# ET6801 register map
Vendor: ETMCU Inc.; File version: v0.0.1
CPU: CM7 r2p1, little endian, MPU, FPU, I-cache, D-cache, ITCM, DTCM, 4 interrupt priority bits
Registers are 32-bit, read-write, reset 0x0 unless marked. A register's access mark holds for its fields unless they carry their own. Offsets are from the block's base; [hi:lo] are bit positions; {n}, {i} and the like mark numbered series.

## I2C0 — Provide an overview of the purpose and functionality of the peripheral: I2C
Base 0x40508000
Same registers: I2C1 0x40509000, I2C2 0x4050A000
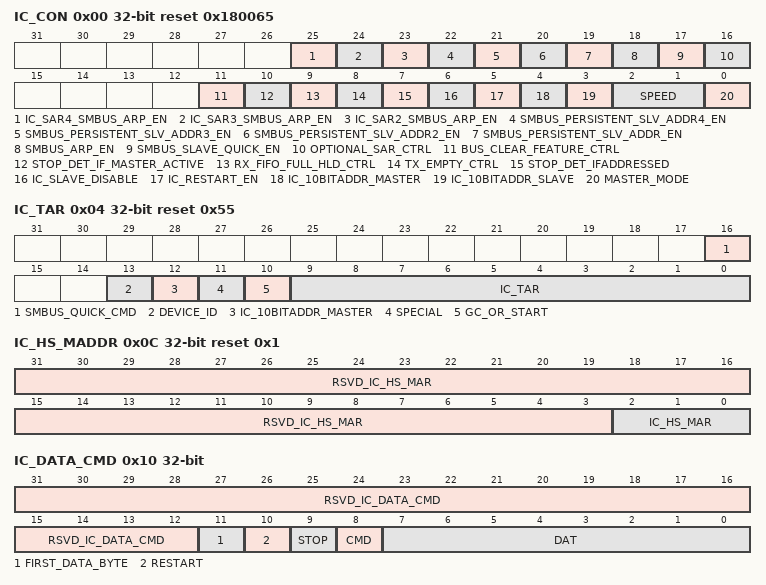
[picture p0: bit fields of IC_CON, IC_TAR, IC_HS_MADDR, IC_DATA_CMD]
0x00 IC_CON reset 0x180065 — I2C Control Register
  [25] IC_SAR4_SMBUS_ARP_EN — This bit controls whether DW_apb_i2c should enable Address Resolution Logic in SMBus Mode for IC_SAR4 Slave Address. The Slave mode will decode the Address Resolution Protocol commands and respond to it. The DW_apb_i2c slave also includes the generation/validity of PEC byte for Address Resolution Protocol commands. This bit is applicable only in Slave mode
  [24] IC_SAR3_SMBUS_ARP_EN — This bit controls whether DW_apb_i2c should enable Address Resolution Logic in SMBus Mode for IC_SAR3 Slave Address. The Slave mode will decode the Address Resolution Protocol commands and respond to it. The DW_apb_i2c slave also includes the generation/validity of PEC byte for Address Resolution Protocol commands. This bit is applicable only in Slave mode
  [23] IC_SAR2_SMBUS_ARP_EN — This bit controls whether DW_apb_i2c should enable Address Resolution Logic in SMBus Mode for IC_SAR2 Slave Address. The Slave mode will decode the Address Resolution Protocol commands and respond to it. The DW_apb_i2c slave also includes the generation/validity of PEC byte for Address Resolution Protocol commands. This bit is applicable only in Slave mode
  [22] SMBUS_PERSISTENT_SLV_ADDR4_EN — The bit controls to enable DW_apb_i2c slave with Slave address 4 (IC_SAR4) as persistent or non persistent slave. If the slave is non-PSA then DW_apb_i2c slave device clears the Address valid flag for both General and Directed Reset ARP command else the address valid flag will always set to 1. This bit is applicable only in Slave mode
  [21] SMBUS_PERSISTENT_SLV_ADDR3_EN — The bit controls to enable DW_apb_i2c slave with Slave address 3 (IC_SAR3) as persistent or non persistent slave. If the slave is non-PSA then DW_apb_i2c slave device clears the Address valid flag for both General and Directed Reset ARP command else the address valid flag will always set to 1. This bit is applicable only in Slave mode
  [20] SMBUS_PERSISTENT_SLV_ADDR2_EN — The bit controls to enable DW_apb_i2c slave with Slave address 2 (IC_SAR2) as persistent or non persistent slave. If the slave is non-PSA then DW_apb_i2c slave device clears the Address valid flag for both General and Directed Reset ARP command else the address valid flag will always set to 1. This bit is applicable only in Slave mode
  [19] SMBUS_PERSISTENT_SLV_ADDR_EN — The bit controls to enable DW_apb_i2c slave as persistent or non persistent slave. If the slave is non-PSA then DW_apb_i2c slave device clears the Address valid flag for both General and Directed Reset ARP command else the address valid flag will always set to 1. This bit is applicable only in Slave mode.
  [18] SMBUS_ARP_EN — This bit controls whether DW_apb_i2c should enable Address Resolution Logic in SMBus Mode. The Slave mode will decode the Address Resolution Protocol commands and respond to it. The DW_apb_i2c slave also includes the generation/validity of PEC byte for Address Resolution Protocol commands. This bit is applicable only in Slave mode.
  [17] SMBUS_SLAVE_QUICK_EN — If this bit is set to 1, DW_apb_i2c slave only receives Quick commands in SMBus Mode. If this bit is set to 0, DW_apb_i2c slave receives all bus protocols but not Quick commands. This bit is applicable only in slave mode.
  [16] OPTIONAL_SAR_CTRL — Enables the usage of IC_OPTIONAL_SAR register. If IC_OPTIONAL_SAR = 1, IC_OPTIONAL_SAR value is used as additional slave address. User must program a valid address in IC_OPTIONAL_SAR before writing 1 to this field. If IC_OPTIONAL_SAR = 0, IC_OPTIONAL_SAR value is not used as additional slave
  [11] BUS_CLEAR_FEATURE_CTRL — This bit controls whether the DW_apb_i2c enables the bus clear feature. For more information, refer to sections "Bus Clear Feature" and "SMBus/PMBus".
  [10] STOP_DET_IF_MASTER_ACTIVE — In Master mode
  [9] RX_FIFO_FULL_HLD_CTRL — This bit controls whether DW_apb_i2c should hold the bus when the Rx FIFO is physically full to its RX_BUFFER_DEPTH, as described in the IC_RX_FULL_HLD_BUS_EN parameter.
  [8] TX_EMPTY_CTRL — This bit controls the generation of the TX_EMPTY interrupt, as described in the IC_RAW_INTR_STAT register.
  [7] STOP_DET_IFADDRESSED — In slave mode
  [6] IC_SLAVE_DISABLE — This bit controls whether I2C has its slave disabled, which means once the presetn signal is applied, then this bit takes on the value of the configuration parameter IC_SLAVE_DISABLE. You have the choice of having the slave enabled or disabled after reset is applied, which means software does not have to configure the slave. By default, the slave is always enabled (in reset state as well). If you need to disable it after reset, set this bit to 1. If this bit is set (slave is disabled), DW_apb_i2c functions only as a master and does not perform any action that requires a slave. Note: Software should ensure that if this bit is written with 0, then bit 0 should also be written with a 0.
  [5] IC_RESTART_EN — Determines whether RESTART conditions may be sent when acting as a master. Some older slaves do not support handling RESTART conditions; however, RESTART conditions are used in several DW_apb_i2c operations. When RESTART is disabled, the master is prohibited from performing the following functions: ■ Sending a START BYTE ■ Performing any high-speed mode operation ■ High-speed mode operation ■ Performing direction changes in combined format mode ■ Performing a read operation with a 10-bit address By replacing RESTART condition followed by a STOP and a subsequent START condition, split operations are broken down into multiple DW_apb_i2c transfers. If the above operations are performed, it will result in setting bit 6 (TX_ABRT) of the IC_RAW_INTR_STAT register.
  [4] IC_10BITADDR_MASTER — If the I2C_DYNAMIC_TAR_UPDATE configuration parameter is set to 'No' (0), this bit is named IC_10BITADDR_MASTER and controls whether the DW_apb_i2c starts its transfers in 7- or 10-bit addressing mode when acting as a master. If I2C_DYNAMIC_TAR_UPDATE is set to 'Yes' (1), the function of this bit is handled by bit 12 of IC_TAR register, and becomes a read-only copy called IC_10BITADDR_MASTER_rd_only.
  [3] IC_10BITADDR_SLAVE — When acting as a slave, this bit controls whether the DW_apb_i2c responds to 7- or 10-bit addresses. ■ 0: 7-bit addressing. The DW_apb_i2c ignores transactions that involve 10-bit addressing; for 7-bit addressing, only the lower 7 bits of the IC_SAR register are compared. ■ 1: 10-bit addressing. The DW_apb_i2c responds to only 10-bit addressing transfers that match the full 10 bits of the IC_SAR register.
  [2:1] SPEED — These bits control at which speed the DW_apb_i2c operates; its setting is relevant only if one is operating the DW_apb_i2c in master mode. Hardware protects against illegal values being programmed by software. These bits must be programmed appropriately for slave mode also, as it is used to capture correct value of spike filter as per the speed mode. This register should be programmed only with a value in the range of 1 to IC_MAX_SPEED_MODE; otherwise, hardware updates this register with the value of IC_MAX_SPEED_MODE. 1: standard mode (100 kbit/s) 2: fast mode 3: high speed mode (3.4 Mbit/s)
  [0] MASTER_MODE — This bit controls whether the DW_apb_i2c master is enabled. Note: Software should ensure that if this bit is written with '1' then bit 6 should also be written with a '1'.
0x04 IC_TAR reset 0x55 — I2C Target Address Register
  [16] SMBUS_QUICK_CMD — If bit 11 (SPECIAL) is set to 1, then this bit indicates whether a Quick command is to be performed by the DW_apb_i2c.
  [13] DEVICE_ID — If bit 11 (SPECIAL) is set to 1, then this bit indicates whether a Device-ID of a particular slave mentioned in IC_TAR[9:0] is to be performed by the DW_apb_i2c Master.
  [12] IC_10BITADDR_MASTER — This bit controls whether the DW_apb_i2c starts its transfers in 7- or 10-bit addressing mode when acting as a master.
  [11] SPECIAL — This bit indicates whether software performs a Device-ID or General Call or START BYTE command.
  [10] GC_OR_START — If bit 11 (SPECIAL) is set to 1 and bit 13(Device-ID) is set to 0, then this bit indicates whether a General Call or START byte command is to be performed by the DW_apb_i2c.
  [9:0] IC_TAR — This is the target address for any master transaction. When transmitting a General Call, these bits are ignored. To generate a START BYTE, the CPU needs to write only once into these bits. If the IC_TAR and IC_SAR are the same, loopback exists but the FIFOs are shared between master and slave, so full loopback is not feasible. A master cannot transmit to itself; it can transmit to only a slave. Value After Reset: IC_DEFAU
0x08 IC_SAR reset 0x55 — I2C Slave Address Register
  [9:0] IC_SAR — The IC_SAR holds the slave address when the I2C is operating as a slave. For 7-bit addressing, only IC_SAR[6:0] is used. This register can be written only when the I2C interface is disabled, which corresponds to the IC_ENABLE[0] register being set to 0. Writes at other times have no effect.
0x0C IC_HS_MADDR reset 0x1 — I2C High Speed Master Mode Code Address Register
  [31:3] RSVD_IC_HS_MAR ro — IC_HS_MAR Reserved bits - Read Only
  [2:0] IC_HS_MAR — This bit field holds the value of the I2C HS mode master code. HS-mode master codes are reserved 8-bit codes (00001xxx) that are not used for slave addressing or other purposes. Each master has its unique master code; up to eight high-speed mode masters can be present on the same I2C bus system. Valid values are from 0 to 7. This register goes away and becomes read-only returning 0's if the IC_MAX_SPEED_MODE configuration parameter is set to either Standard (1) or Fast (2). This register can be written only when the I2C interface is disabled, which corresponds to the IC_ENABLE[0] register being set to 0. Writes at other times have no effect.
0x10 IC_DATA_CMD — I2C Rx/Tx Data Buffer and Command Register; this is the register the CPU writes to when filling the TX FIFO and the CPU reads from when retrieving bytes from RX FIFO.
  [31:12] RSVD_IC_DATA_CMD ro — IC_DATA_CMD Reserved bits - Read Only
  [11] FIRST_DATA_BYTE ro — Indicates the first data byte received after the address phase for receive transfer in Master receiver or Slave receiver mode.
  [10] RESTART wo — This bit controls whether a RESTART is issued before the byte is sent or received. This bit is available only if IC_EMPTYFIFO_HOLD_MASTER_EN is configured to 1.
  [9] STOP wo — This bit controls whether a STOP is issued after the byte is sent or received.
  [8] CMD wo — This bit controls whether a read or a write is performed. This bit does not control the direction when the DW_apb_i2c acts as a slave. It controls only the direction when it acts as a master.
  [7:0] DAT — This register contains the data to be transmitted or received on the I2C bus. If you are writing to this register and want to perform a read, bits 7:0 (DAT) are ignored by the DW_apb_i2c. However, when you read this register, these bits return the value of data received on the DW_apb_i2c interface.
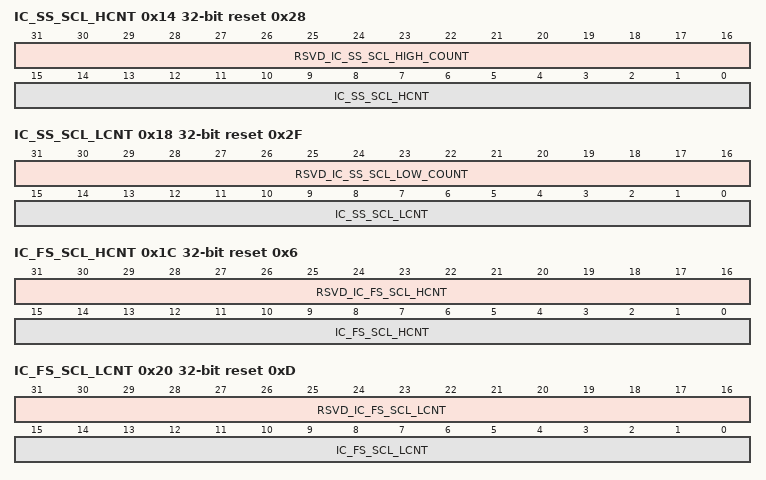
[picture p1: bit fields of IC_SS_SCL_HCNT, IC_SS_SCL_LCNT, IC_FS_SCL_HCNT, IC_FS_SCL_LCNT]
0x14 IC_SS_SCL_HCNT reset 0x28 — Standard Speed I2C Clock SCL High Count Register
  [31:16] RSVD_IC_SS_SCL_HIGH_COUNT ro — IC_SS_SCL_HCNT Reserved bits - Read Only
  [15:0] IC_SS_SCL_HCNT — This register must be set before any I2C bus transaction can take place to ensure proper I/O timing. This register sets the SCL clock high-period count for standard speed.
0x18 IC_SS_SCL_LCNT reset 0x2F — Standard Speed I2C Clock SCL Low Count Register
  [31:16] RSVD_IC_SS_SCL_LOW_COUNT ro — RSVD_IC_SS_SCL_LOW_COUNT Reserved bits - Read Only
  [15:0] IC_SS_SCL_LCNT — This register must be set before any I2C bus transaction can take place to ensure proper I/O timing. This register sets the SCL clock low period count for standard speed.
0x1C IC_FS_SCL_HCNT reset 0x6 — Fast Mode or Fast Mode Plus I2C Clock SCL High Count Register
  [31:16] RSVD_IC_FS_SCL_HCNT ro — IC_FS_SCL_HCNT Reserved bits - Read Only
  [15:0] IC_FS_SCL_HCNT — This register must be set before any I2C bus transaction can take place to ensure proper I/O timing. This register sets the SCL clock high-period count for fast mode or fast mode plus. It is used in high-speed mode to send the Master Code and START BYTE or General CALL.
0x20 IC_FS_SCL_LCNT reset 0xD — Fast Mode or Fast Mode Plus I2C Clock SCL Low Count Register
  [31:16] RSVD_IC_FS_SCL_LCNT ro — IC_FS_SCL_LCNT Reserved bits - Read Only
  [15:0] IC_FS_SCL_LCNT — This register must be set before any I2C bus transaction can take place to ensure proper I/O timing. This register sets the SCL clock low period count for fast speed. It is used in high speed mode to send the Master Code and START BYTE or General CALL.
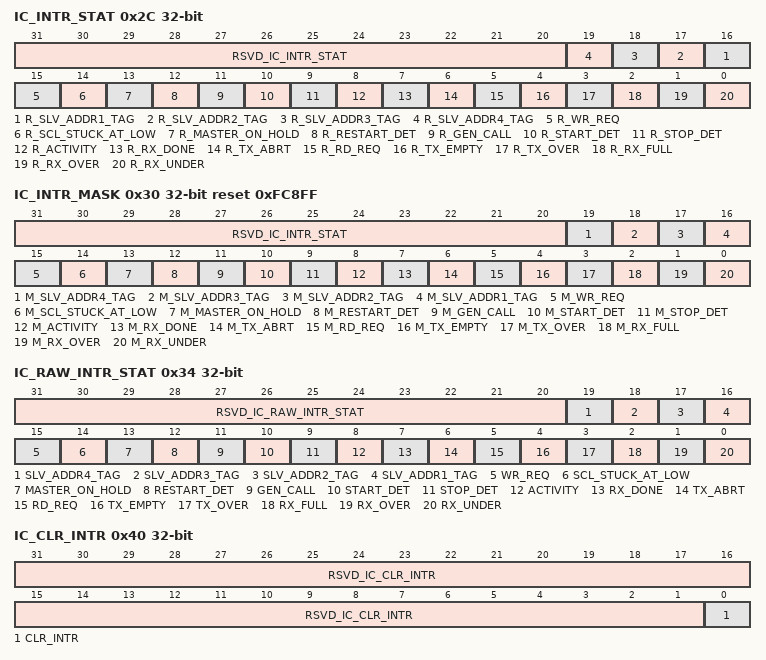
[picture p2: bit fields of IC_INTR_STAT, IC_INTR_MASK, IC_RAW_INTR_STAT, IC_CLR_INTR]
0x2C IC_INTR_STAT ro — I2C Interrupt Status Register
  [31:20] RSVD_IC_INTR_STAT — IC_INTR_STAT Reserved bits - Read Only
  [n+15] R_SLV_ADDR{n}_TAG (n=1..4) — See IC_RAW_INTR_STAT for a detailed description of R_SLV_ADDR{n}_TAG bit.
  [15] R_WR_REQ — See IC_RAW_INTR_STAT for a detailed description of R_WR_REQ bit.
  [14] R_SCL_STUCK_AT_LOW — See IC_RAW_INTR_STAT for a detailed description of R_SCL_STUCK_AT_LOW bit.
  [13] R_MASTER_ON_HOLD — See IC_RAW_INTR_STAT for a detailed description of R_MASTER_ON_HOLD bit.
  [12] R_RESTART_DET — See IC_RAW_INTR_STAT for a detailed description of R_RESTART_DET bit.
  [11] R_GEN_CALL — See IC_RAW_INTR_STAT for a detailed description of R_GEN_CALL bit.
  [10] R_START_DET — See IC_RAW_INTR_STAT for a detailed description of R_START_DET bit.
  [9] R_STOP_DET — See IC_RAW_INTR_STAT for a detailed description of R_STOP_DET bit.
  [8] R_ACTIVITY — See IC_RAW_INTR_STAT for a detailed description of R_ACTIVITY bit.
  [7] R_RX_DONE — See IC_RAW_INTR_STAT for a detailed description of R_RX_DONE bit.
  [6] R_TX_ABRT — See IC_RAW_INTR_STAT for a detailed description of R_TX_ABRT bit.
  [5] R_RD_REQ — See IC_RAW_INTR_STAT for a detailed description of R_RD_REQ bit.
  [4] R_TX_EMPTY — See IC_RAW_INTR_STAT for a detailed description of R_TX_EMPTY bit.
  [3] R_TX_OVER — See IC_RAW_INTR_STAT for a detailed description of R_TX_OVER bit.
  [2] R_RX_FULL — See IC_RAW_INTR_STAT for a detailed description of R_RX_FULL bit.
  [1] R_RX_OVER — See IC_RAW_INTR_STAT for a detailed description of R_RX_OVER bit.
  [0] R_RX_UNDER — See IC_RAW_INTR_STAT for a detailed description of R_RX_UNDER bit.
0x30 IC_INTR_MASK reset 0xFC8FF — I2C Interrupt Mask Register.
  [31:20] RSVD_IC_INTR_STAT ro — IC_INTR_STAT Reserved bits - Read Only
  [19] M_SLV_ADDR4_TAG ro — This bit masks the R_SLV_ADDR4_TAG interrupt in IC_INTR_STAT register.
  [18] M_SLV_ADDR3_TAG ro — This bit masks the R_SLV_ADDR3_TAG interrupt in IC_INTR_STAT register.
  [17] M_SLV_ADDR2_TAG — This bit masks the R_SLV_ADDR2_TAG interrupt in IC_INTR_STAT register.
  [16] M_SLV_ADDR1_TAG — This bit masks the R_SLV_ADDR1_TAG interrupt in IC_INTR_STAT register.
  [15] M_WR_REQ — This bit masks the R_WR_REQ interrupt in IC_INTR_STAT register.
  [14] M_SCL_STUCK_AT_LOW — This bit masks the R_SCL_STUCK_AT_LOW interrupt in IC_INTR_STAT register.
  [13] M_MASTER_ON_HOLD — This bit masks the R_MASTER_ON_HOLD interrupt in IC_INTR_STAT register.
  [12] M_RESTART_DET — This bit masks the R_RESTART_DET interrupt in IC_INTR_STAT register.
  [11] M_GEN_CALL — This bit masks the R_GEN_CALL interrupt in IC_INTR_STAT register.
  [10] M_START_DET — This bit masks the R_START_DET interrupt in IC_INTR_STAT register.
  [9] M_STOP_DET — This bit masks the R_STOP_DET interrupt in IC_INTR_STAT register.
  [8] M_ACTIVITY — This bit masks the R_ACTIVITY interrupt in IC_INTR_STAT register.
  [7] M_RX_DONE — This bit masks the R_RX_DONE interrupt in IC_INTR_STAT register.
  [6] M_TX_ABRT — This bit masks the R_TX_ABRT interrupt in IC_INTR_STAT register.
  [5] M_RD_REQ — This bit masks the R_RD_REQ interrupt in IC_INTR_STAT register.
  [4] M_TX_EMPTY — This bit masks the R_TX_EMPTY interrupt in IC_INTR_STAT register.
  [3] M_TX_OVER — This bit masks the R_TX_OVER interrupt in IC_INTR_STAT register.
  [2] M_RX_FULL — This bit masks the R_RX_FULL interrupt in IC_INTR_STAT register.
  [1] M_RX_OVER — This bit masks the R_RX_OVER interrupt in IC_INTR_STAT register.
  [0] M_RX_UNDER — This bit masks the R_RX_UNDER interrupt in IC_INTR_STAT register.
0x34 IC_RAW_INTR_STAT ro — I2C Raw Interrupt Status Register.
  [31:20] RSVD_IC_RAW_INTR_STAT — IC_RAW_INTR_STAT Reserved bits - Read Only
  [19] SLV_ADDR4_TAG — This bit is set to 1 when DW_apb_i2c is acting as slave and another I2C master is attempting to write/read I2C transfers with the Slave address IC_SAR4.
  [18] SLV_ADDR3_TAG — This bit is set to 1 when DW_apb_i2c is acting as slave and another I2C master is attempting to write/read I2C transfers with the Slave address IC_SAR3.
  [17] SLV_ADDR2_TAG — This bit is set to 1 when DW_apb_i2c is acting as slave and another I2C master is attempting to write/read I2C transfers with the Slave address IC_SAR2.
  [16] SLV_ADDR1_TAG — This bit is set to 1 when DW_apb_i2c is acting as slave and another I2C master is attempting to write/read I2C transfers with the Slave address IC_SAR.
  [15] WR_REQ — This bit is set to 1 when DW_apb_i2c is acting as slave and another I2C master is attempting to werite data into DW_apb_i2c.
  [14] SCL_STUCK_AT_LOW — Indicates whether the SCL Line is stuck at low for the IC_SCL_STUCK_LOW_TIMEOUT number of ic_clk periods. Enabled only when IC_BUS_CLEAR_FEATURE=1 and IC_ULTRA_FAST_MODE=0.
  [13] MASTER_ON_HOLD — Indicates whether master is holding the bus and TX FIFO is empty. Enabled only when I2C_DYNAMIC_TAR_UPDATE=1 and IC_EMPTYFIFO_HOLD_MASTER_EN=1.
  [12] RESTART_DET — Indicates whether a RESTART condition has occurred on the I2C interface when DW_apb_i2c is operating in Slave mode and the slave is being addressed.
  [11] GEN_CALL — Set only when a General Call address is received and it is acknowledged. It stays set until it is cleared either by disabling DW_apb_i2c or when the CPU reads bit 0 of the IC_CLR_GEN_CALL register. DW_apb_i2c stores the received data in the Rx buffer.
  [10] START_DET — Indicates whether a START or RESTART condition has occurred on the I2C interface regardless of whether DW_apb_i2c is operating in slave or master mode.
  [9] STOP_DET — Indicates whether a STOP condition has occurred on the I2C interface regardless of whether DW_apb_i2c is operating in slave or master mode.
  [8] ACTIVITY — This bit captures DW_apb_i2c activity and stays set until it is cleared.
  [7] RX_DONE — When the DW_apb_i2c is acting as a slave-transmitter, this bit is set to 1 if the master does not acknowledge a transmitted byte. This occurs on the last byte of the transmission, indicating that the transmission is done.
  [6] TX_ABRT — This bit indicates if DW_apb_i2c, as an I2C transmitter, is unable to complete the intended actions on the contents of the transmit FIFO. This situation can occur both as an I2C master or an I2C slave, and is referred to as a 'transmit abort'. When this bit is set to 1, the IC_TX_ABRT_SOURCE register indicates the reason why the transmit abort takes places.
  [5] RD_REQ — This bit is set to 1 when DW_apb_i2c is acting as a slave and another I2C master is attempting to read data from DW_apb_i2c.
  [4] TX_EMPTY — The behavior of the TX_EMPTY interrupt status differs based on the TX_EMPTY_CTRL selection in the IC_CON register.
  [3] TX_OVER — Set during transmit if the transmit buffer is filled to IC_TX_BUFFER_DEPTH and the processor attempts to issue another I2C command by writing to the IC_DATA_CMD register. When the module is disabled, this bit keeps its level until the master or slave state machines go into idle, and when ic_en goes to 0, this interrupt is cleared.
  [2] RX_FULL — Set when the receive buffer reaches or goes above the RX_TL threshold in the IC_RX_TL register. It is automatically cleared by hardware when buffer level goes below the threshold. If the module is disabled (IC_ENABLE[0]=0), the RX FIFO is flushed and held in reset; therefore the RX FIFO is not full. So this bit is cleared once the IC_ENABLE bit 0 is programmed with a 0, regardless of the activity that continues.
  [1] RX_OVER — Set if the receive buffer is completely filled to IC_RX_BUFFER_DEPTH and an additional byte is received from an external I2C device. The DW_apb_i2c acknowledges this, but any data bytes received after the FIFO is full are lost. If the module is disabled (IC_ENABLE[0]=0), this bit keeps its level until the master or slave state machines go into idle, and when ic_en goes to 0, this interrupt is cleared.
  [0] RX_UNDER — Set if the processor attempts to read the receive buffer when it is empty by reading from the IC_DATA_CMD register. If the module is disabled (IC_ENABLE[0]=0), this bit keeps its level until the master or slave state machines go into idle, and when ic_en goes to 0, this interrupt is cleared.
0x38 IC_RX_TL reset 0x8 — I2C Receive FIFO Threshold Register
  [7:0] RX_TL — Receive FIFO Threshold Level.
0x3C IC_TX_TL reset 0x8 — I2C Transmit FIFO Threshold Register
  [7:0] TX_TL — Transmit FIFO Threshold Level.
0x40 IC_CLR_INTR ro — Clear Combined and Individual Interrupt Register
  [31:1] RSVD_IC_CLR_INTR — CLR_INTR Reserved bits - Read Only
  [0] CLR_INTR — Read this register to clear the combined interrupt, all individual interrupts, and the IC_TX_ABRT_SOURCE register. This bit does not clear hardware clearable interrupts but software clearable interrupts.
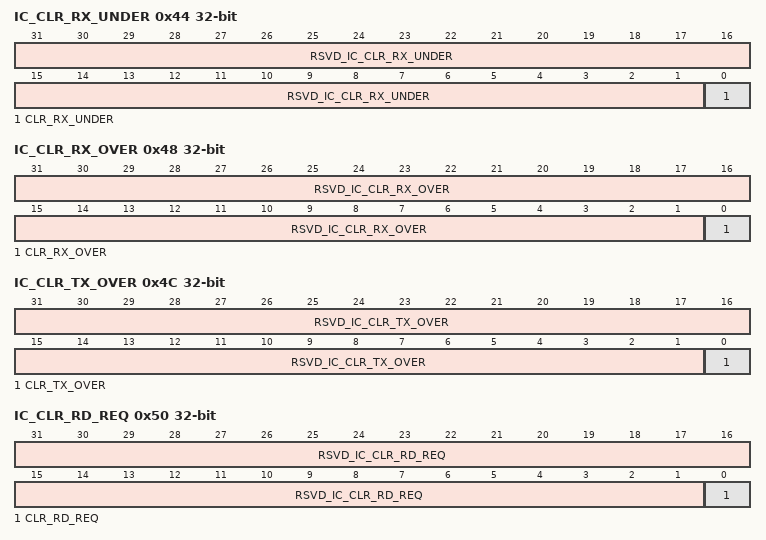
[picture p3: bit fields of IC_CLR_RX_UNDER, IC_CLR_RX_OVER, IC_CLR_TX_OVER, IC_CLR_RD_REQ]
0x44 IC_CLR_RX_UNDER ro — Clear RX_UNDER Interrupt Register
  [31:1] RSVD_IC_CLR_RX_UNDER — IC_CLR_RX_UNDER Reserved bits - Read Only
  [0] CLR_RX_UNDER — Read this register to clear the RX_UNDER interrupt (bit 0) of the IC_RAW_INTR_STAT register.
0x48 IC_CLR_RX_OVER ro — Clear RX_OVER Interrupt Register
  [31:1] RSVD_IC_CLR_RX_OVER — IC_CLR_RX_OVER Reserved bits - Read Only
  [0] CLR_RX_OVER — Read this register to clear the RX_OVER interrupt (bit 1) of the IC_RAW_INTR_STAT register.
0x4C IC_CLR_TX_OVER ro — Clear TX_OVER Interrupt Register
  [31:1] RSVD_IC_CLR_TX_OVER — IC_CLR_TX_OVER Reserved bits - Read Only
  [0] CLR_TX_OVER — Read this register to clear the TX_OVER interrupt (bit 3) of the IC_RAW_INTR_STAT register.
0x50 IC_CLR_RD_REQ ro — Clear RD_REQ Interrupt Register
  [31:1] RSVD_IC_CLR_RD_REQ — IC_CLR_RD_REQ Reserved bits - Read Only
  [0] CLR_RD_REQ — Read this register to clear the RD_REQ interrupt (bit 5) of the IC_RAW_INTR_STAT register.
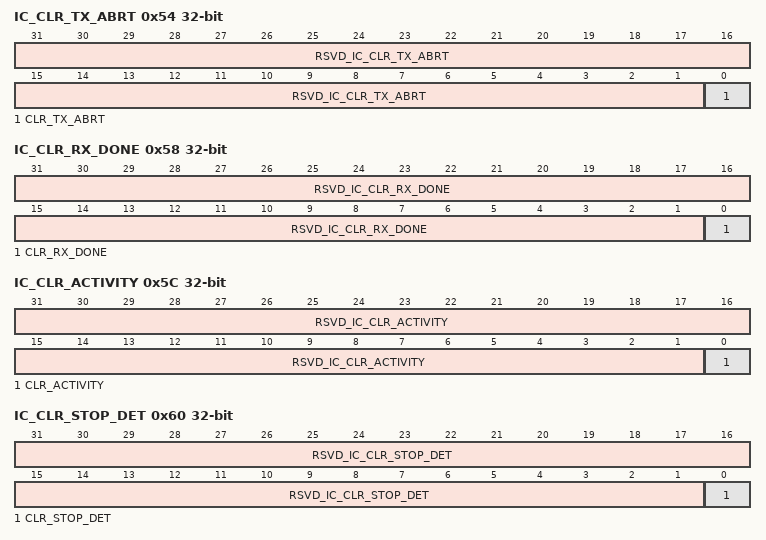
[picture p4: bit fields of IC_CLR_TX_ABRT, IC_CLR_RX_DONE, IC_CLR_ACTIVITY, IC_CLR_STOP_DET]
0x54 IC_CLR_TX_ABRT ro — Clear TX_ABRT Interrupt Register
  [31:1] RSVD_IC_CLR_TX_ABRT — IC_CLR_TX_ABRT Reserved bits - Read Only
  [0] CLR_TX_ABRT — Read this register to clear the TX_ABRT interrupt (bit 6) of the IC_RAW_INTR_STAT register, and the IC_TX_ABRT_SOURCE register. This also releases the TX FIFO from the flushed/reset state, allowing more writes to the TX FIFO.
0x58 IC_CLR_RX_DONE ro — Clear RX_DONE Interrupt Register
  [31:1] RSVD_IC_CLR_RX_DONE — IC_CLR_RX_DONE Reserved bits - Read Only
  [0] CLR_RX_DONE — Read this register to clear the RX_DONE interrupt (bit 7) of the IC_RAW_INTR_STAT register.
0x5C IC_CLR_ACTIVITY ro — Clear ACTIVITY Interrupt Register
  [31:1] RSVD_IC_CLR_ACTIVITY — IC_CLR_ACTIVITY Reserved bits - Read Only
  [0] CLR_ACTIVITY — Reading this register clears the ACTIVITY interrupt if the I2C is not active anymore.
0x60 IC_CLR_STOP_DET ro — Clear STOP_DET Interrupt Register
  [31:1] RSVD_IC_CLR_STOP_DET — IC_CLR_STOP_DET Reserved bits - Read Only
  [0] CLR_STOP_DET — Read this register to clear the STOP_DET interrupt (bit 9) of the IC_RAW_INTR_STAT register.
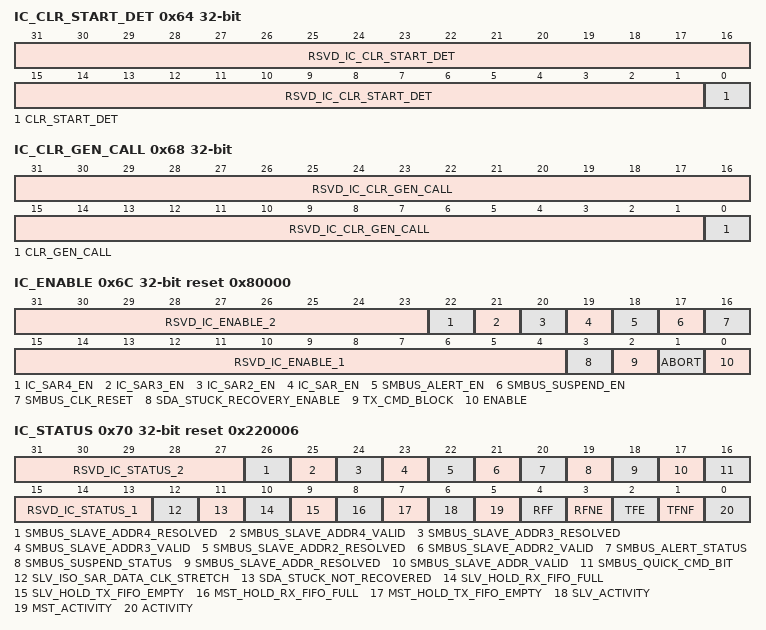
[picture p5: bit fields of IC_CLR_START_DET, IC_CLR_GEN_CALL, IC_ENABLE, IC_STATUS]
0x64 IC_CLR_START_DET ro — Clear START_DET Interrupt Register
  [31:1] RSVD_IC_CLR_START_DET — IC_CLR_START_DET Reserved bits - Read Only
  [0] CLR_START_DET — Read this register to clear the START_DET interrupt (bit 10) of the IC_RAW_INTR_STAT register.
0x68 IC_CLR_GEN_CALL ro — Clear GEN_CALL Interrupt Register
  [31:1] RSVD_IC_CLR_GEN_CALL — IC_CLR_GEN_CALL Reserved bits - Read Only
  [0] CLR_GEN_CALL — Read this register to clear the GEN_CALL interrupt (bit 11) of IC_RAW_INTR_STAT register.
0x6C IC_ENABLE reset 0x80000 — I2C Enable Register
  [31:23] RSVD_IC_ENABLE_2 ro — IC_ENABLE Reserved bits - Read Only
  [22] IC_SAR4_EN ro — Controls whether the DW_apb_i2c SAR4 is enabled. If IC_SAR4_EN bit of the IC_ENABLE register is set to 1, then the DW_apb_i2c will acknowledge the address if it corresponds to IC_SAR4 and completes the I2C transfers as intended. Otherwise, the I2C transfer address will be Nacked.
  [21] IC_SAR3_EN ro — Controls whether the DW_apb_i2c SAR3 is enabled. If IC_SAR3_EN bit of the IC_ENABLE register is set to 1, then the DW_apb_i2c will acknowledge the address if it corresponds to IC_SAR3 and completes the I2C transfers as intended. Otherwise, the I2C transfer address will be Nacked.
  [20] IC_SAR2_EN — Controls whether the DW_apb_i2c SAR2 is enabled. If IC_SAR2_EN bit of the IC_ENABLE register is set to 1, then the DW_apb_i2c will acknowledge the address if it corresponds to IC_SAR2 and completes the I2C transfers as intended. Otherwise, the I2C transfer address will be Nacked.
  [19] IC_SAR_EN — Controls whether the DW_apb_i2c SAR is enabled. If IC_SAR_EN bit of the IC_ENABLE register is set to 1, then the DW_apb_i2c will acknowledge the address if it corresponds to IC_SAR and completes the I2C transfers as intended. Otherwise, the I2C transfer address will be Nacked
  [18] SMBUS_ALERT_EN — The SMBUS_ALERT_CTRL register bit is used to control assertion of SMBALERT signal.
  [17] SMBUS_SUSPEND_EN — The SMBUS_SUSPEND_EN register bit is used to control assertion and de-assertion of SMBSUS signal.
  [16] SMBUS_CLK_RESET — This bit is used in SMBus Host mode to initiate the SMBus Master Clock Reset. This bit should be enabled only when Master is in idle. Whenever this bit is enabled, the SMBCLK is held low for the IC_SCL_STUCK_TIMEOUT ic_clk cycles to reset the SMBus slave devices.
  [15:4] RSVD_IC_ENABLE_1 ro — RSVD_IC_ENABLE_1 Reserved bits - Read Only
  [3] SDA_STUCK_RECOVERY_ENABLE — If SDA is stuck at low indicated through the TX_ABORT interrupt (IC_TX_ABRT_SOURCE[17]), then this bit is used as a control knob to initiate the SDA Recovery Mechanism (that is, send at most 9 SCL clocks and STOP to release the SDA line) and then this bit gets auto clear
  [2] TX_CMD_BLOCK — In Master mode
  [1] ABORT — When set, the controller initiates the transfer abort.
  [0] ENABLE — Controls whether the DW_apb_i2c is enabled.
0x70 IC_STATUS ro reset 0x220006 — I2C Status Register.
  [31:27] RSVD_IC_STATUS_2 — IC_STATUS Reserved bits - Read Only
  [26] SMBUS_SLAVE_ADDR4_RESOLVED — This bit indicates whether the slave address 4 (IC_SAR4) is resolved by the ARP Master.
  [25] SMBUS_SLAVE_ADDR4_VALID — This bit indicates whether the slave address 4 (IC_SAR4) is valid or not.
  [24] SMBUS_SLAVE_ADDR3_RESOLVED — This bit indicates whether the slave address 3 (IC_SAR3) is resolved by the ARP Master.
  [23] SMBUS_SLAVE_ADDR3_VALID — This bit indicates whether the slave address 3 (IC_SAR3) is valid or not.
  [22] SMBUS_SLAVE_ADDR2_RESOLVED — This bit indicates whether the slave address 2 (IC_SAR2) is resolved by the ARP Master.
  [21] SMBUS_SLAVE_ADDR2_VALID — This bit indicates whether the slave address 2 (IC_SAR2) is valid or not.
  [20] SMBUS_ALERT_STATUS — This bit indicates the status of the SMBus Alert signal (ic_smbalert_in_n). This signal is asserted when the SMBus Alert signal is asserted by the SMBus Device.
  [19] SMBUS_SUSPEND_STATUS — This bit indicates the status of the SMBus Suspend signal (ic_smbsus_in_n). This signal is asserted when the SMBus Suspend signal is asserted by the SMBus Host.
  [18] SMBUS_SLAVE_ADDR_RESOLVED — This bit indicates whether the slave address (ic_sar) is resolved by the ARP Master.
  [17] SMBUS_SLAVE_ADDR_VALID — This bit indicates whether the slave address (ic_sar) is valid or not.
  [16] SMBUS_QUICK_CMD_BIT — This bit indicates the read-write bit of the Quick command received. This bit will be cleared after the user has read this bit.
  [15:13] RSVD_IC_STATUS_1 — RSVD_IC_STATUS_1 Reserved bits - Read Only
  [12] SLV_ISO_SAR_DATA_CLK_STRETCH — This bit indicates the Bus hold (clock stretching) in Slave mode with Multiple SAR feature - for isolating the write transfer related data corresponding to one slave address with another slave address.
  [11] SDA_STUCK_NOT_RECOVERED — This bit indicates that SDA stuck at low is not recovered after the recovery mechanism. In Slave mode, this register bit is not applicable.
  [10] SLV_HOLD_RX_FIFO_FULL — This bit indicates the BUS Hold in Slave mode due to Rx FIFO is Full and an additional byte has been received (This kind of Bus hold is applicable
  [9] SLV_HOLD_TX_FIFO_EMPTY — This bit indicates the BUS Hold in Slave mode for the Read request when the Tx FIFO is empty. The Bus is in hold until the Tx FIFO has data to Transmit for the read request.
  [8] MST_HOLD_RX_FIFO_FULL — This bit indicates the BUS Hold in Master mode due to Rx FIFO is Full and additional byte has been received (This kind of Bus hold is applicable
  [7] MST_HOLD_TX_FIFO_EMPTY — If the IC_EMPTYFIFO_HOLD_MASTER_EN parameter is set to 1, the DW_apb_i2c master stalls the write transfer when Tx FIFO is empty, and the the last byte does not have the Stop bit set. This bit indicates the BUS hold when the master holds the bus because of the Tx FIFO being empty, and the the previous transferred command does not have the Stop bit set.
  [6] SLV_ACTIVITY — Slave FSM Activity Status. When the Slave Finite State Machine (FSM) is not in the IDLE state, this bit is set.
  [5] MST_ACTIVITY — Master FSM Activity Status. When the Master Finite State Machine (FSM) is not in the IDLE state, this bit is set.
  [4] RFF — Receive FIFO Completely Full. When the receive FIFO is completely full, this bit is set. When the receive FIFO contains one or more empty location, this bit is cleared.
  [3] RFNE — Receive FIFO Not Empty. This bit is set when the receive FIFO contains one or more entries; it is cleared when the receive FIFO is empty.
  [2] TFE — Transmit FIFO Completely Empty. When the transmit FIFO is completely empty, this bit is set. When it contains one or more valid entries, this bit is cleared. This bit field does not request an interrupt.
  [1] TFNF — Transmit FIFO Not Full. Set when the transmit FIFO contains one or more empty locations, and is cleared when the FIFO is full.
  [0] ACTIVITY — I2C Activity Status.
0x74 IC_TXFLR ro — I2C Transmit FIFO Level Register.
  [5:0] TXFLR — Transmit FIFO Level. Contains the number of valid data entries in the transmit FIFO.
0x78 IC_RXFLR ro — I2C Receive FIFO Level Register.
  [5:0] RXFLR — Receive FIFO Level. Contains the number of valid data entries in the receive FIFO.
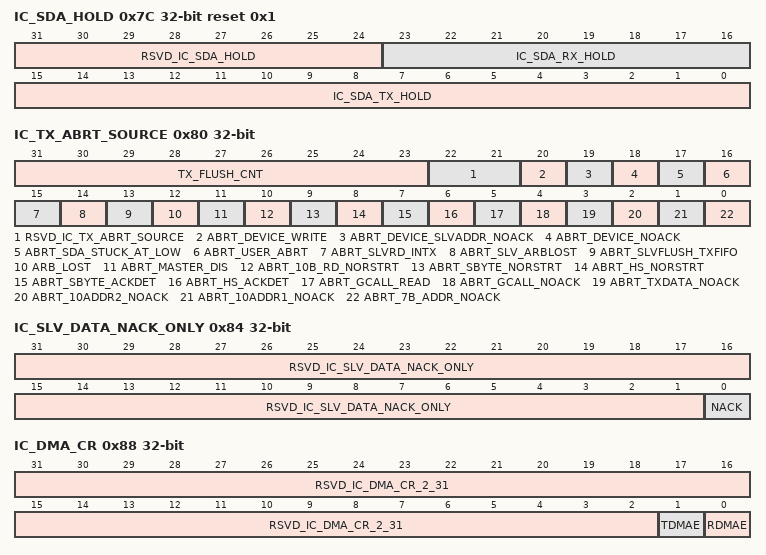
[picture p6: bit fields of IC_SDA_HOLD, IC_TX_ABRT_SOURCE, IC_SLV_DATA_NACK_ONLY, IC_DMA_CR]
0x7C IC_SDA_HOLD reset 0x1 — I2C SDA Hold Time Length Register.
  [31:24] RSVD_IC_SDA_HOLD ro — IC_SDA_HOLD Reserved bits - Read Only
  [23:16] IC_SDA_RX_HOLD — Sets the required SDA hold time in units of ic_clk period, when DW_apb_i2c acts as a receiver.
  [15:0] IC_SDA_TX_HOLD — Sets the required SDA hold time in units of ic_clk period, when DW_apb_i2c acts as a transmitter.
0x80 IC_TX_ABRT_SOURCE ro — I2C Transmit Abort Source Register.
  [31:23] TX_FLUSH_CNT — This field indicates the number of Tx FIFO Data Commands which are flushed due to TX_ABRT interrupt. It is cleared whenever I2C is disabled.
  [22:21] RSVD_IC_TX_ABRT_SOURCE — IC_TX_ABRT_SOURCE Reserved bits - Read Only
  [20] ABRT_DEVICE_WRITE — This is a master-mode-only bit. Master is initiating the DEVICE_ID transfer and the Tx-FIFO consists of write commands.
  [19] ABRT_DEVICE_SLVADDR_NOACK — This is a master-mode-only bit. Master is initiating the DEVICE_ID transfer and the slave address sent was not acknowledged by any slave.
  [18] ABRT_DEVICE_NOACK — This is a master-mode-only bit. Master is initiating the DEVICE_ID transfer and the device id sent was not acknowledged by any slave.
  [17] ABRT_SDA_STUCK_AT_LOW — This is a master-mode-only bit. Master detects the SDA Stuck at low for the IC_SDA_STUCK_AT_LOW_TIMEOUT value of ic_clks.
  [16] ABRT_USER_ABRT — This is a master-mode-only bit. Master has detected the transfer abort
  [15] ABRT_SLVRD_INTX — When the processor side responds to a slave mode request for data to be transmitted to a remote master and user writes a 1 in CMD (bit 8) of IC_DATA_CMD register.
  [14] ABRT_SLV_ARBLOST — This field indicates that a Slave has lost the bus while transmitting data to a remote master.
  [13] ABRT_SLVFLUSH_TXFIFO — This field specifies that the Slave has received a read command and some data exists in the TX FIFO, so the slave issues a TX_ABRT interrupt to flush old data in TX FIFO.
  [12] ARB_LOST — This field specifies that the Master has lost arbitration, or if IC_TX_ABRT_SOURCE[14] is also set, then the slave transmitter has lost arbitration.
  [11] ABRT_MASTER_DIS — This field indicates that the User tries to initiate a Master operation with the Master mode disabled.
  [10] ABRT_10B_RD_NORSTRT — This field indicates that the restart is disabled (IC_RESTART_EN bit (IC_CON[5]) =0) and the master sends a read command in 10-bit addressing mode.
  [9] ABRT_SBYTE_NORSTRT — To clear Bit 9, the source of the ABRT_SBYTE_NORSTRT must be fixed first; restart must be enabled (IC_CON[5]=1), the SPECIAL bit must be cleared (IC_TAR[11]), or the GC_OR_START bit must be cleared (IC_TAR[10]). Once the source of the ABRT_SBYTE_NORSTRT is fixed, then this bit can be cleared in the same manner as other bits in this register. If the source of the ABRT_SBYTE_NORSTRT is not fixed before attempting to clear this bit, bit 9 clears for one cycle and then gets reasserted. When this field is set to 1, the restart is disabled (IC_RESTART_EN bit (IC_CON[5]) =0) and the user is trying to send a START Byte.
  [8] ABRT_HS_NORSTRT — This field indicates that the restart is disabled (IC_RESTART_EN bit (IC_CON[5]) =0) and the user is trying to use the master to transfer data in High Speed mode.
  [7] ABRT_SBYTE_ACKDET — This field indicates that the Master has sent a START Byte and the START Byte was acknowledged (wrong behavior).
  [6] ABRT_HS_ACKDET — This field indicates that the Master is in High Speed mode and the High Speed Master code was acknowledged (wrong behavior).
  [5] ABRT_GCALL_READ — This field indicates that DW_apb_i2c in the master mode has sent a General Call but the user programmed the byte following the General Call to be a read from the bus
  [4] ABRT_GCALL_NOACK — This field indicates that DW_apb_i2c in master mode has sent a General Call and no slave on the bus acknowledged the General Call.
  [3] ABRT_TXDATA_NOACK — This field indicates the master-mode only bit. When the master receives an acknowledgement for the address, but when it sends data byte(s) following the address, it did not receive an acknowledge from the remote slave(s).
  [2] ABRT_10ADDR2_NOACK — This field indicates that the Master is in 10-bit address mode and that the second address byte of the 10-bit address was not acknowledged by any slave.
  [1] ABRT_10ADDR1_NOACK — This field indicates that the Master is in 10-bit address mode and the first 10-bit address byte was not acknowledged by any slave.
  [0] ABRT_7B_ADDR_NOACK — This field indicates that the Master is in 7-bit addressing mode and the address sent was not acknowledged by any slave.
0x84 IC_SLV_DATA_NACK_ONLY — Generate Slave Data NACK Register
  [31:1] RSVD_IC_SLV_DATA_NACK_ONLY ro — IC_SLV_DATA_NACK_ONLY Reserved bits - Read Only
  [0] NACK — Generate NACK. This NACK generation only occurs when DW_apb_i2c is a slave-receiver. If this register is set to a value of 1, it can only generate a NACK after a data byte is received; hence, the data transfer is aborted and the data received is not pushed to the receive buffer.
0x88 IC_DMA_CR — DMA Control Register.
  [31:2] RSVD_IC_DMA_CR_2_31 ro — RSVD_IC_DMA_CR_2_31 Reserved bits - Read Only
  [1] TDMAE — Transmit DMA Enable. This bit enables/disables the transmit FIFO DMA channel.
  [0] RDMAE — Receive DMA Enable. This bit enables/disables the receive FIFO DMA channel.
0x8C IC_DMA_TDLR — DMA Transmit Data Level Register.
  [4:0] DMATDL — Transmit Data Level.
0x90 IC_DMA_RDLR — I2C Receive Data Level Register.
  [4:0] DMARDL — Receive Data Level.
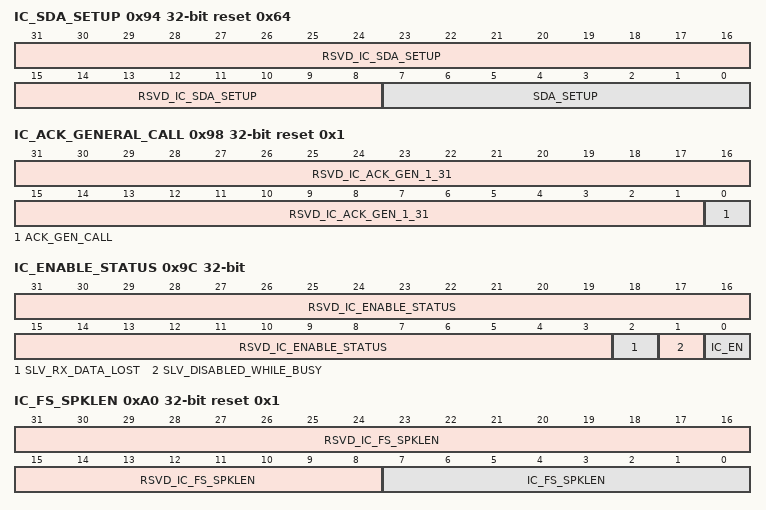
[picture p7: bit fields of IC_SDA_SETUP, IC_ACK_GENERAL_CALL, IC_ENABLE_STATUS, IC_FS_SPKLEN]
0x94 IC_SDA_SETUP reset 0x64 — I2C SDA Setup Register.
  [31:8] RSVD_IC_SDA_SETUP ro — IC_SDA_SETUP Reserved bits - Read Only
  [7:0] SDA_SETUP — SDA Setup (tSU:DAT). It is recommended that if the required delay is 1000ns, then for an ic_clk frequency of 10 MHz
0x98 IC_ACK_GENERAL_CALL reset 0x1 — I2C ACK General Call Register.
  [31:1] RSVD_IC_ACK_GEN_1_31 ro — RSVD_IC_ACK_GEN_1_31 Reserved bits - Read Only
  [0] ACK_GEN_CALL — ACK General Call. When set to 1, DW_apb_i2c responds with a ACK (by asserting ic_data_oe) when it receives a General Call. Otherwise, DW_apb_i2c responds with a NACK (by negating ic_data_oe).
0x9C IC_ENABLE_STATUS — I2C Enable Status Register.
  [31:3] RSVD_IC_ENABLE_STATUS ro — IC_ENABLE_STATUS Reserved bits - Read Only
  [2] SLV_RX_DATA_LOST ro — Slave Received Data Lost.
  [1] SLV_DISABLED_WHILE_BUSY ro — Slave Disabled While Busy (Transmit, Receive). T
  [0] IC_EN ro — IC Enable Status.
0xA0 IC_FS_SPKLEN reset 0x1 — I2C SS, FS or FM+ Spike Suppression Limit.
  [31:8] RSVD_IC_FS_SPKLEN ro — IC_FS_SPKLEN Reserved bits - Read Only
  [7:0] IC_FS_SPKLEN — This register must be set before any I2C bus transaction can take place to ensure stable operation.
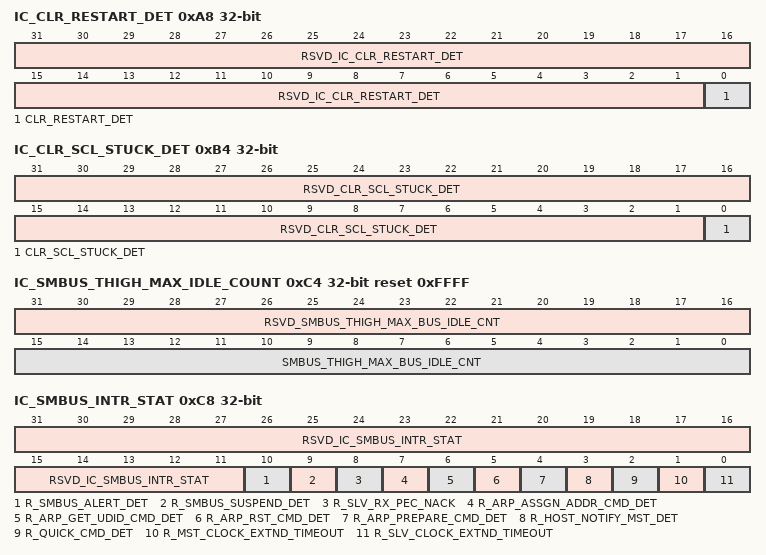
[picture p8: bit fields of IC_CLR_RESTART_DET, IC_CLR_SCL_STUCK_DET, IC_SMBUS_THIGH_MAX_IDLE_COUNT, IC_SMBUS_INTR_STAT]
0xA8 IC_CLR_RESTART_DET ro — Clear RESTART_DET Interrupt Register
  [31:1] RSVD_IC_CLR_RESTART_DET — IC_CLR_RESTART_DET Reserved bits - Read Only
  [0] CLR_RESTART_DET — Read this register to clear the RESTART_DET interrupt (bit 12) of IC_RAW_INTR_STAT register.
0xAC IC_SCL_STUCK_AT_LOW_TIMEOUT reset 0xFFFFFFFF — I2C SCL Stuck at Low Timeout.
  [31:0] IC_SCL_STUCK_LOW_TIMEOUT — DW_apb_i2c generate the interrupt to indicate SCL stuck at low (ic_scl_stuck_at_low_intr/ic_scl_stuck_at_low_intr_n) if it detects the SCL stuck at low for the IC_SCL_STUCK_LOW_TIMEOUT in units of ic_clk period. This register can be written only when the I2C interface is disabled which corresponds to the IC_ENABLE[0] register being set to 0. Writes at other times have no effect.
0xB0 IC_SDA_STUCK_AT_LOW_TIMEOUT reset 0xFFFFFFFF — I2C SDA Stuck at Low Timeout.
  [31:0] IC_SDA_STUCK_LOW_TIMEOUT — DW_apb_i2c initiates the recovery of SDA line through enabling the SDA_STUCK_RECOVERY_EN (IC_ENABLE[3]) register bit, if it detects the SDA stuck at low for the IC_SDA_STUCK_LOW_TIMEOUT in units of ic_clk period.
0xB4 IC_CLR_SCL_STUCK_DET — Clear SCL Stuck at Low Detect Interrupt Register
  [31:1] RSVD_CLR_SCL_STUCK_DET ro — CLR_SCL_STUCK_DET Reserved bits - Read Only
  [0] CLR_SCL_STUCK_DET ro — Read this register to clear the SCL_STUCT_AT_LOW interrupt (bit 15) of the IC_RAW_INTR_STAT register.
0xBC IC_SMBUS_CLK_LOW_SEXT reset 0xFFFFFFFF — SMBus Slave Clock Extend Timeout Register.
  [31:0] SMBUS_CLK_LOW_SEXT_TIMEOUT — This field is used to detect the Slave Clock Extend timeout (tLOW:SEXT) in master mode extended by the slave device in one message from the initial START to the STOP. The values in this register are in units of ic_clk period.
0xC0 IC_SMBUS_CLK_LOW_MEXT reset 0xFFFFFFFF — SMBus Master Clock Extend Timeout Register.
  [31:0] SMBUS_CLK_LOW_MEXT_TIMEOUT — This field is used to detect the Master extend SMBus clock (SCLK) timeout defined from START-to-ACK, ACK-to-ACK, or ACK-to-STOP in Master mode. The values in this register are in units of ic_clk period.
0xC4 IC_SMBUS_THIGH_MAX_IDLE_COUNT reset 0xFFFF — SMBus Master THigh MAX Bus-idle count Register.
  [31:16] RSVD_SMBUS_THIGH_MAX_BUS_IDLE_CNT ro — SMBUS_THIGH_MAX_BUS_IDLE_CNT Reserved bits - Read Only
  [15:0] SMBUS_THIGH_MAX_BUS_IDLE_CNT — This field is used to set the required Bus-Idle time period used when a master has been dynamically added to the bus and may not have detected a state transition on the SMBCLK or SMBDAT lines.
0xC8 IC_SMBUS_INTR_STAT ro — SMBUS Interrupt Status Register.
  [31:11] RSVD_IC_SMBUS_INTR_STAT — IC_SMBUS_INTR_STAT Reserved bits - Read Only
  [10] R_SMBUS_ALERT_DET — See IC_SMBUS_RAW_INTR_STAT for a detailed description of R_SMBUS_ALERT_DET bit.
  [9] R_SMBUS_SUSPEND_DET — See IC_SMBUS_RAW_INTR_STAT for a detailed description of R_SMBUS_SUSPEND_DET bit.
  [8] R_SLV_RX_PEC_NACK — See IC_SMBUS_RAW_INTR_STAT for a detailed description of R_SLV_RX_PEC_NACK bit.
  [7] R_ARP_ASSGN_ADDR_CMD_DET — See IC_SMBUS_RAW_INTR_STAT for a detailed description of R_ARP_ASSGN_ADDR_CMD_DET bit.
  [6] R_ARP_GET_UDID_CMD_DET — See IC_SMBUS_RAW_INTR_STAT for a detailed description of R_ARP_GET_UDID_CMD_DET bit.
  [5] R_ARP_RST_CMD_DET — See IC_SMBUS_RAW_INTR_STAT for a detailed description of R_ARP_RST_CMD_DET bit.
  [4] R_ARP_PREPARE_CMD_DET — See IC_SMBUS_RAW_INTR_STAT for a detailed description of R_ARP_PREPARE_CMD_DET bit.
  [3] R_HOST_NOTIFY_MST_DET — See IC_SMBUS_RAW_INTR_STAT for a detailed description of R_HOST_NOTIFY_MST_DET bit.
  [2] R_QUICK_CMD_DET — See IC_SMBUS_RAW_INTR_STAT for a detailed description of R_QUICK_CMD_DET bit.
  [1] R_MST_CLOCK_EXTND_TIMEOUT — See IC_SMBUS_RAW_INTR_STAT for a detailed description of R_MST_CLOCK_EXTND_TIMEOUT bit.
  [0] R_SLV_CLOCK_EXTND_TIMEOUT — See IC_SMBUS_RAW_INTR_STAT for a detailed description of R_SLV_CLOCK_EXTND_TIMEOUT bit.
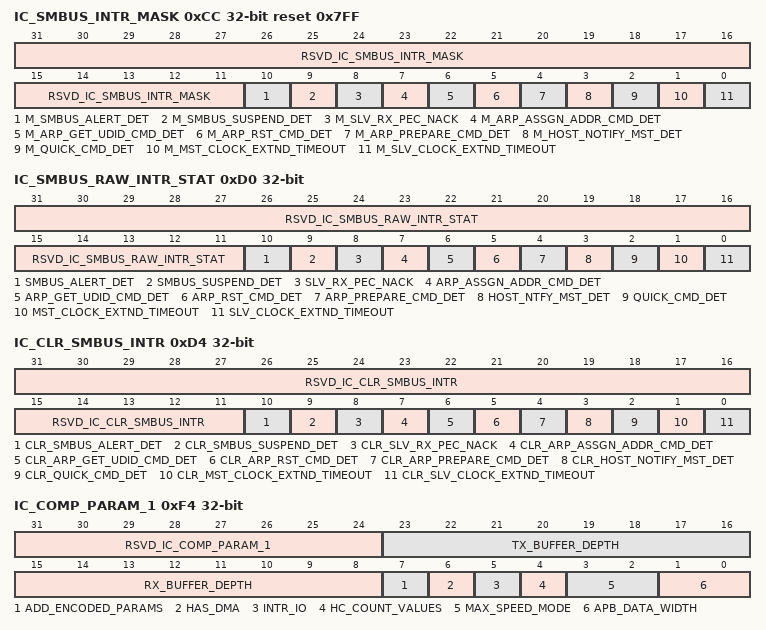
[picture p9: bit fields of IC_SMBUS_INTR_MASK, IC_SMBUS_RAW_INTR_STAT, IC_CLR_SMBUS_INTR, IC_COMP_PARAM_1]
0xCC IC_SMBUS_INTR_MASK reset 0x7FF — SMBus Interrupt Mask Register
  [31:11] RSVD_IC_SMBUS_INTR_MASK ro — IC_SMBUS_INTR_MASK Reserved bits - Read Only
  [10] M_SMBUS_ALERT_DET — This bit masks the R_SMBUS_ALERT_DET interrupt in IC_SMBUS_INTR_STAT register.
  [9] M_SMBUS_SUSPEND_DET — This bit masks the M_SMBUS_SUSPEND_DET interrupt in IC_SMBUS_INTR_STAT register.
  [8] M_SLV_RX_PEC_NACK — This bit masks the R_SLV_RX_PEC_NACK interrupt in IC_SMBUS_INTR_STAT register.
  [7] M_ARP_ASSGN_ADDR_CMD_DET — This bit masks the R_ARP_ASSGN_ADDR_CMD_DET interrupt in IC_SMBUS_INTR_STAT register.
  [6] M_ARP_GET_UDID_CMD_DET — This bit masks the R_ARP_GET_UDID_CMD_DET interrupt in IC_SMBUS_INTR_STAT register.
  [5] M_ARP_RST_CMD_DET — This bit masks the R_ARP_RST_CMD_DET interrupt in IC_SMBUS_INTR_STAT register.
  [4] M_ARP_PREPARE_CMD_DET — This bit masks the R_ARP_PREPARE_CMD_DET interrupt in IC_SMBUS_INTR_STAT register.
  [3] M_HOST_NOTIFY_MST_DET — This bit masks the R_HOST_NOTIFY_MST_DET interrupt in IC_SMBUS_INTR_STAT register.
  [2] M_QUICK_CMD_DET — This bit masks the R_QUICK_CMD_DET interrupt in IC_SMBUS_INTR_STAT register.
  [1] M_MST_CLOCK_EXTND_TIMEOUT — This bit masks the R_MST_CLOCK_EXTND_TIMEOUT interrupt in IC_SMBUS_INTR_STAT register.
  [0] M_SLV_CLOCK_EXTND_TIMEOUT — This bit masks the R_SLV_CLOCK_EXTND_TIMEOUT interrupt in IC_SMBUS_INTR_STAT register.
0xD0 IC_SMBUS_RAW_INTR_STAT — SMBus Raw Interrupt Status Register.
  [31:11] RSVD_IC_SMBUS_RAW_INTR_STAT ro — IC_SMBUS_RAW_INTR_STAT Reserved bits - Read Only
  [10] SMBUS_ALERT_DET ro — Indicates whether a SMBALERT (ic_smbalert_in_n) signal is driven low by the slave.
  [9] SMBUS_SUSPEND_DET ro — Indicates whether a SMBSUS (ic_smbsus_in_n) signal is driven low by the Host.
  [8] SLV_RX_PEC_NACK ro — Indicates whether a NACK has been sent due to PEC mismatch while working as ARP slave.
  [7] ARP_ASSGN_ADDR_CMD_DET ro — Indicates whether an Assign Address ARP command has been received.
  [6] ARP_GET_UDID_CMD_DET ro — Indicates whether a Get UDID ARP command has been received.
  [5] ARP_RST_CMD_DET ro — Indicates whether a General or Directed Reset ARP command has been received.
  [4] ARP_PREPARE_CMD_DET ro — Indicates whether a prepare to ARP command has been received.
  [3] HOST_NTFY_MST_DET ro — Indicates whether a Notify ARP Master ARP command has been received.
  [2] QUICK_CMD_DET ro — Indicates whether a Quick command has been received on the SMBus interface regardless of whether DW_apb_i2c is operating in slave or master mode. Enabled only when IC_SMBUS=1 is set to 1.
  [1] MST_CLOCK_EXTND_TIMEOUT ro — Indicates whether the Master device transaction from START to STOP exceeds IC_SMBUS_CLOCK_LOW_MEXT time with in each byte of message.
  [0] SLV_CLOCK_EXTND_TIMEOUT ro — Indicates whether the transaction from Slave (i.e from START to STOP) exceeds IC_SMBUS_CLK_LOW_SEXT time.
0xD4 IC_CLR_SMBUS_INTR wo — SMBus Clear Interrupt Register
  [31:11] RSVD_IC_CLR_SMBUS_INTR — IC_CLR_SMBUS_INTR Reserved bits - Read Only
  [10] CLR_SMBUS_ALERT_DET — Write this register bit to clear the SMBUS_ALERT_DET interrupt (bit 10) of the IC_SMBUS_RAW_INTR_STAT register.
  [9] CLR_SMBUS_SUSPEND_DET — Write this register bit to clear the SMBUS_SUSPEND_DET interrupt (bit 9) of the IC_SMBUS_RAW_INTR_STAT register.
  [8] CLR_SLV_RX_PEC_NACK — Write this register bit to clear the SLV_RX_PEC_NACK interrupt (bit 8) of the IC_SMBUS_RAW_INTR_STAT register.
  [7] CLR_ARP_ASSGN_ADDR_CMD_DET — Write this register bit to clear the ARP_ASSGN_ADDR_CMD_DET interrupt (bit 7) of the IC_SMBUS_RAW_INTR_STAT register.
  [6] CLR_ARP_GET_UDID_CMD_DET — Write this register bit to clear the ARP_GET_UDID_CMD_DET interrupt (bit 6) of the IC_SMBUS_RAW_INTR_STAT register.
  [5] CLR_ARP_RST_CMD_DET — Write this register bit to clear the ARP_RST_CMD_DET interrupt (bit 5) of the IC_SMBUS_RAW_INTR_STAT register.
  [4] CLR_ARP_PREPARE_CMD_DET — Write this register bit to clear the ARP_PREPARE_CMD_DET interrupt (bit 4) of the IC_SMBUS_RAW_INTR_STAT register.
  [3] CLR_HOST_NOTIFY_MST_DET — Write this register bit to clear the HOST_NOTIFY_MST_DET interrupt (bit 3) of the IC_SMBUS_RAW_INTR_STAT register.
  [2] CLR_QUICK_CMD_DET — Write this register bit to clear the QUICK_CMD_DET interrupt (bit 2) of the IC_SMBUS_RAW_INTR_STAT register.
  [1] CLR_MST_CLOCK_EXTND_TIMEOUT — Write this register bit to clear the MST_CLOCK_EXTND_TIMEOUT interrupt (bit 1) of the IC_SMBUS_RAW_INTR_STAT register.
  [0] CLR_SLV_CLOCK_EXTND_TIMEOUT — Write this register bit to clear the SLV_CLOCK_EXTND_TIMEOUT interrupt (bit 0) of the IC_SMBUS_RAW_INTR_STAT register.
0xDC IC_SMBUS_UDID_LSB reset 0xFFFFFFFF — SMBUS ARP UDID LSB Register.
  [31:0] SMBUS_UDID_LSB — This field is used to store the LSB 32 bit value of slave unique device identifier used in Address Resolution Protocol.
0xF4 IC_COMP_PARAM_1 ro — Component Parameter Register 1
  [31:24] RSVD_IC_COMP_PARAM_1 — IC_COMP_PARAM_1 Reserved bits - Read Only
  [23:16] TX_BUFFER_DEPTH — The value of this register is derived from the IC_TX_BUFFER_DEPTH coreConsultant parameter.
  [15:8] RX_BUFFER_DEPTH — The value of this register is derived from the IC_RX_BUFFER_DEPTH coreConsultant parameter.
  [7] ADD_ENCODED_PARAMS — The value of this register is derived from the IC_ADD_ENCODED_PARAMS coreConsultant parameter. Reading 1 in this bit means that the capability of reading these encoded parameters via software has been included. Otherwise, the entire register is 0 regardless of the setting of any other parameters that are encoded in the bits.
  [6] HAS_DMA — The value of this register is derived from the IC_HAS_DMA coreConsultant parameter.
  [5] INTR_IO — The value of this register is derived from the IC_INTR_IO coreConsultant parameter.
  [4] HC_COUNT_VALUES — The value of this register is derived from the IC_HC_COUNT VALUES coreConsultant parameter.
  [3:2] MAX_SPEED_MODE — The value of this register is derived from the IC_MAX_SPEED_MODE coreConsultant parameter.
  [1:0] APB_DATA_WIDTH — The value of this register is derived from the APB_DATA_WIDTH coreConsultant parameter.
0xF8 IC_COMP_VERSION ro — I2C Component Version Register
  [31:0] IC_COMP_VERSION — Specific values for this register are described in the Releases Table in the DW_apb_i2c Release Notes
0xFC IC_COMP_TYPE ro — I2C Component Type Register
  [31:0] IC_COMP_TYPE — DesignWare Component Type number = 0x44_57_01_40. This assigned unique hex value is constant and is derived from the two ASCII letters 'DW' followed by a 16-bit unsigned number.
0x100 IC_SAR2 — I2C Slave Address Register 2
  [9:0] IC_SAR2 — The IC_SAR2 holds the slave address 2 when the I2C is operating as a slave.
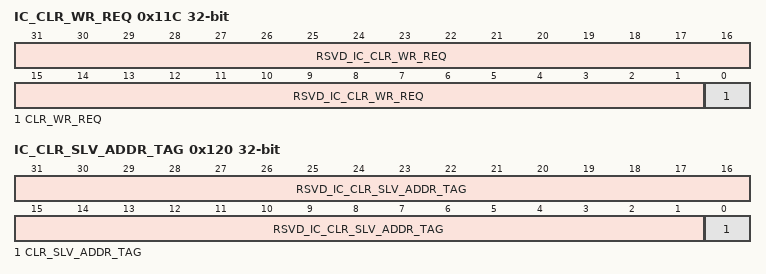
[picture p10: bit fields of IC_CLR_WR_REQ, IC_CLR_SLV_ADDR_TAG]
0x11C IC_CLR_WR_REQ — Clear WR_REQ Interrupt Register
  [31:1] RSVD_IC_CLR_WR_REQ ro — IC_CLR_WR_REQ Reserved bits - Read Only
  [0] CLR_WR_REQ ro — Read this register to clear the WR_REQ interrupt (bit 15) of the IC_RAW_INTR_STAT register.
0x120 IC_CLR_SLV_ADDR_TAG — Clear CLR_SLV_ADDR_TAG Interrupt Register
  [31:1] RSVD_IC_CLR_SLV_ADDR_TAG ro — IC_CLR_SLV_ADDR_TAG Reserved bits - Read Only
  [0] CLR_SLV_ADDR_TAG ro — Read this register to clear all SLV_ADDRx_TAG (Where x is 1 through IC_NUM_SARS) interrupts (bit 16 ...(16+IC_NUM_SARS-1)) of the IC_RAW_INTR_STAT register.
